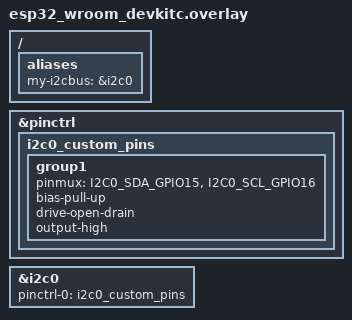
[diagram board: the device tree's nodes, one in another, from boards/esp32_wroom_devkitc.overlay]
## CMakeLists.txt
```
cmake_minimum_required(VERSION 3.20.0)

find_package(Zephyr REQUIRED HINTS $ENV{ZEPHYR_BASE})
project(I2c_Scanner)

target_sources(app PRIVATE src/main.c)
```

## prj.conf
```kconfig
CONFIG_LOG=y

CONFIG_I2C=y    #Enable I2C
CONFIG_PINCTRL=y    #Enable PINCTRL
```

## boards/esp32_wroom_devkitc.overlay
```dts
/{
    aliases{
        my-i2cbus = &i2c0;
    };
};

&pinctrl {
    i2c0_custom_pins: i2c0_custom_pins {    
        group1 {
            pinmux = <I2C0_SDA_GPIO15>, <I2C0_SCL_GPIO16>;  // GPIO15 as SDA, GPIO16 as SCL
            bias-pull-up;
            drive-open-drain;
            output-high;
        };
    };
};

&i2c0 {
    status = "okay";    // Enable I2C0
    pinctrl-0 = <&i2c0_custom_pins>; // Apply custom pin configuration
    pinctrl-names = "default";
};
```

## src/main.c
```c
#include <stdio.h>
#include <zephyr/kernel.h>
#include <zephyr/drivers/i2c.h>

static const struct device *const i2c_dev = DEVICE_DT_GET(DT_ALIAS(my_i2cbus));

int main(void){
    int ret;
    uint8_t dummy = 0x00;

    if(!device_is_ready(i2c_dev)){
        printk("Device %s is not ready.\n", i2c_dev->name);
        return 0;
    }
    printk("I2C scanner started\n");
    printk("Scanning addresses 0x03 to 0x77\n");

    for(uint8_t addr = 0x03; addr <= 0x77; addr++){

        /* Zero-length write is enough to test ACK */
        ret = i2c_write(i2c_dev, &dummy, 0, addr);

        if (ret == 0) {
            printk("✔ Device found at 0x%02X\n", addr);
        }

        k_msleep(5);  // small delay to be polite on the bus
    }

    printk("I2C scan complete\n");

    return 0;
}
```
